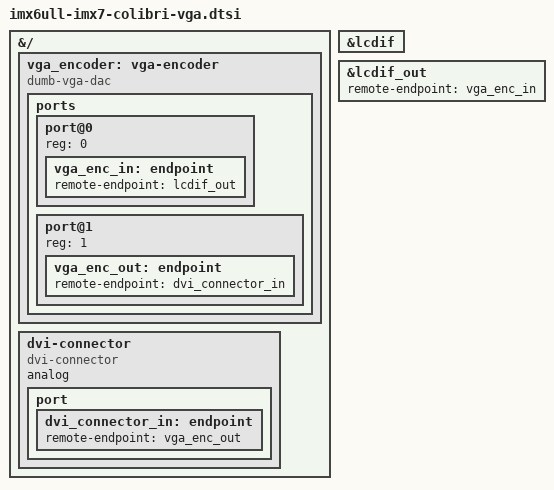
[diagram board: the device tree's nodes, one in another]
// SPDX-License-Identifier: GPL-2.0-only OR MIT
/*
 * Copyright (c) Toradex
 *
 * VGA output connected to the Colibri parallel RGB LCD interface through a
 * non-programmable video DAC with a DVI connector, shared by the Colibri
 * iMX6ULL eMMC and Colibri iMX7 eMMC overlays.
 *
 * The VGA output is available on multiple carrier boards (including Iris,
 * Eval, Aster) without VESA DDC I2C signals.
 *
 * The DAC power-save input is driven by the BL_ON signal on SODIMM 71, the
 * SoC specific pinctrl and GPIO are described by the overlay including this
 * file.
 */

&{/} {
	vga_encoder: vga-encoder {
		compatible = "dumb-vga-dac";

		ports {
			#address-cells = <1>;
			#size-cells = <0>;

			port@0 {
				reg = <0>;

				vga_enc_in: endpoint {
					remote-endpoint = <&lcdif_out>;
				};
			};

			port@1 {
				reg = <1>;

				vga_enc_out: endpoint {
					remote-endpoint = <&dvi_connector_in>;
				};
			};
		};
	};

	dvi-connector {
		compatible = "dvi-connector";
		analog;

		port {
			dvi_connector_in: endpoint {
				remote-endpoint = <&vga_enc_out>;
			};
		};
	};
};

&lcdif {
	status = "okay";
};

&lcdif_out {
	remote-endpoint = <&vga_enc_in>;
};
